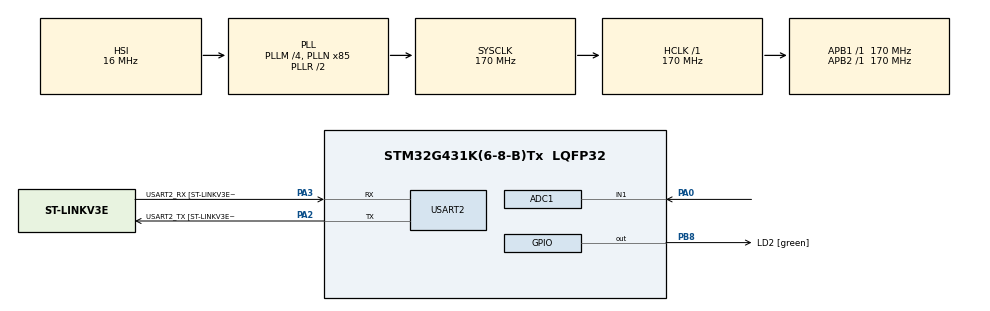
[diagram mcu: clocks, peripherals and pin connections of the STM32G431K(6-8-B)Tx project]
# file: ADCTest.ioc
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ADC1.Channel-0\#ChannelRegularConversion=ADC_CHANNEL_1
ADC1.NbrOfConversionFlag=1
ADC1.OffsetNumber-0\#ChannelRegularConversion=ADC_OFFSET_NONE
ADC1.Rank-0\#ChannelRegularConversion=1
ADC1.SamplingTime-0\#ChannelRegularConversion=ADC_SAMPLETIME_2CYCLES_5
ADC1.master=1
Mcu.Family=STM32G4
Mcu.Name=STM32G431K(6-8-B)Tx
Mcu.Package=LQFP32
NVIC.PriorityGroup=NVIC_PRIORITYGROUP_4
PA0.Mode=IN1-Single-Ended
PA0.Signal=ADC1_IN1
PA13.GPIO_Label=T_SWDIO
PA13.Mode=Serial_Wire
PA13.Signal=SYS_JTMS-SWDIO
PA14.GPIO_Label=T_SWCLK
PA14.Mode=Serial_Wire
PA14.Signal=SYS_JTCK-SWCLK
PA2.GPIO_Label=USART2_TX [ST-LINKV3E_VCP_RX]
PA2.Mode=Asynchronous
PA2.Signal=USART2_TX
PA3.GPIO_Label=USART2_RX [ST-LINKV3E_VCP_TX]
PA3.Mode=Asynchronous
PA3.Signal=USART2_RX
PB3.GPIO_Label=T_SWO
PB3.Signal=SYS_JTDO-SWO
PB8-BOOT0.GPIO_Label=LD2 [green]
PB8-BOOT0.Signal=GPIO_Output
ProjectManager.HeapSize=0x200
ProjectManager.StackSize=0x400
ProjectManager.TargetToolchain=STM32CubeIDE
RCC.ADC12Freq_Value=170000000
RCC.AHBFreq_Value=170000000
RCC.APB1Freq_Value=170000000
RCC.APB1TimFreq_Value=170000000
RCC.APB2Freq_Value=170000000
RCC.APB2TimFreq_Value=170000000
RCC.CortexFreq_Value=170000000
RCC.EXTERNAL_CLOCK_VALUE=12288000
RCC.HCLKFreq_Value=170000000
RCC.HSE_VALUE=8000000
RCC.HSI48_VALUE=48000000
RCC.HSI_VALUE=16000000
RCC.LSE_VALUE=32768
RCC.PLLM=RCC_PLLM_DIV4
RCC.PLLN=85
RCC.SYSCLKFreq_VALUE=170000000
RCC.SYSCLKSource=RCC_SYSCLKSOURCE_PLLCLK
RCC.USBFreq_Value=170000000
RCC.VCOOutputFreq_Value=340000000
USART2.VirtualMode-Asynchronous=VM_ASYNC
USART2.WordLength=WORDLENGTH_8B
board=NUCLEO-G431KB

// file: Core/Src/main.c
/* USER CODE BEGIN Header */
/**
  ******************************************************************************
  * @file           : main.c
  * @brief          : Main program body
  ******************************************************************************
  * @attention
  *
  * Copyright (c) 2022 STMicroelectronics.
  * All rights reserved.
  *
  * This software is licensed under terms that can be found in the LICENSE file
  * in the root directory of this software component.
  * If no LICENSE file comes with this software, it is provided AS-IS.
  *
  ******************************************************************************
  */
/* USER CODE END Header */
#include "main.h"

ADC_HandleTypeDef hadc1;

UART_HandleTypeDef huart2;

void SystemClock_Config(void);
static void MX_GPIO_Init(void);
static void MX_USART2_UART_Init(void);
static void MX_ADC1_Init(void);

int main(void)
{
  /* USER CODE BEGIN 1 */
	__IO uint32_t ad;
	//double v;
	uint8_t buff[10];
  /* USER CODE END 1 */

  /* MCU Configuration--------------------------------------------------------*/

  /* Reset of all peripherals, Initializes the Flash interface and the Systick. */
  HAL_Init();

  /* Configure the system clock */
  SystemClock_Config();

  /* Initialize all configured peripherals */
  MX_GPIO_Init();
  MX_USART2_UART_Init();
  MX_ADC1_Init();

  /* Infinite loop */
  /* USER CODE BEGIN WHILE */
  while (1)
  {
	  HAL_ADC_Start(&hadc1);
	 if (HAL_ADC_PollForConversion(&hadc1, 1000) == HAL_OK){
		 ad = HAL_ADC_GetValue(&hadc1);
		 //v = 3.3 * ad / 4095
	 }
	 HAL_ADC_Stop(&hadc1);

	 snprintf(buff, sizeof(buff), "%d", ad);
	 	  HAL_UART_Transmit(&huart2, buff, sizeof(buff), 100);
	 	  HAL_Delay(100);
    /* USER CODE END WHILE */

  }
}

void SystemClock_Config(void)
{
  RCC_OscInitTypeDef RCC_OscInitStruct = {0};
  RCC_ClkInitTypeDef RCC_ClkInitStruct = {0};

  /** Configure the main internal regulator output voltage
  */
  HAL_PWREx_ControlVoltageScaling(PWR_REGULATOR_VOLTAGE_SCALE1_BOOST);

  /** Initializes the RCC Oscillators according to the specified parameters
  * in the RCC_OscInitTypeDef structure.
  */
  RCC_OscInitStruct.OscillatorType = RCC_OSCILLATORTYPE_HSI;
  RCC_OscInitStruct.HSIState = RCC_HSI_ON;
  RCC_OscInitStruct.HSICalibrationValue = RCC_HSICALIBRATION_DEFAULT;
  RCC_OscInitStruct.PLL.PLLState = RCC_PLL_ON;
  RCC_OscInitStruct.PLL.PLLSource = RCC_PLLSOURCE_HSI;
  RCC_OscInitStruct.PLL.PLLM = RCC_PLLM_DIV4;
  RCC_OscInitStruct.PLL.PLLN = 85;
  RCC_OscInitStruct.PLL.PLLP = RCC_PLLP_DIV2;
  RCC_OscInitStruct.PLL.PLLQ = RCC_PLLQ_DIV2;
  RCC_OscInitStruct.PLL.PLLR = RCC_PLLR_DIV2;
  if (HAL_RCC_OscConfig(&RCC_OscInitStruct) != HAL_OK)
  {
    Error_Handler();
  }

  /** Initializes the CPU, AHB and APB buses clocks
  */
  RCC_ClkInitStruct.ClockType = RCC_CLOCKTYPE_HCLK|RCC_CLOCKTYPE_SYSCLK
                              |RCC_CLOCKTYPE_PCLK1|RCC_CLOCKTYPE_PCLK2;
  RCC_ClkInitStruct.SYSCLKSource = RCC_SYSCLKSOURCE_PLLCLK;
  RCC_ClkInitStruct.AHBCLKDivider = RCC_SYSCLK_DIV1;
  RCC_ClkInitStruct.APB1CLKDivider = RCC_HCLK_DIV1;
  RCC_ClkInitStruct.APB2CLKDivider = RCC_HCLK_DIV1;

  if (HAL_RCC_ClockConfig(&RCC_ClkInitStruct, FLASH_LATENCY_4) != HAL_OK)
  {
    Error_Handler();
  }
}

static void MX_ADC1_Init(void)
{

  ADC_MultiModeTypeDef multimode = {0};
  ADC_ChannelConfTypeDef sConfig = {0};

  /** Common config
  */
  hadc1.Instance = ADC1;
  hadc1.Init.ClockPrescaler = ADC_CLOCK_SYNC_PCLK_DIV4;
  hadc1.Init.Resolution = ADC_RESOLUTION_12B;
  hadc1.Init.DataAlign = ADC_DATAALIGN_RIGHT;
  hadc1.Init.GainCompensation = 0;
  hadc1.Init.ScanConvMode = ADC_SCAN_DISABLE;
  hadc1.Init.EOCSelection = ADC_EOC_SINGLE_CONV;
  hadc1.Init.LowPowerAutoWait = DISABLE;
  hadc1.Init.ContinuousConvMode = DISABLE;
  hadc1.Init.NbrOfConversion = 1;
  hadc1.Init.DiscontinuousConvMode = DISABLE;
  hadc1.Init.ExternalTrigConv = ADC_SOFTWARE_START;
  hadc1.Init.ExternalTrigConvEdge = ADC_EXTERNALTRIGCONVEDGE_NONE;
  hadc1.Init.DMAContinuousRequests = DISABLE;
  hadc1.Init.Overrun = ADC_OVR_DATA_PRESERVED;
  hadc1.Init.OversamplingMode = DISABLE;
  if (HAL_ADC_Init(&hadc1) != HAL_OK)
  {
    Error_Handler();
  }

  /** Configure the ADC multi-mode
  */
  multimode.Mode = ADC_MODE_INDEPENDENT;
  if (HAL_ADCEx_MultiModeConfigChannel(&hadc1, &multimode) != HAL_OK)
  {
    Error_Handler();
  }

  /** Configure Regular Channel
  */
  sConfig.Channel = ADC_CHANNEL_1;
  sConfig.Rank = ADC_REGULAR_RANK_1;
  sConfig.SamplingTime = ADC_SAMPLETIME_2CYCLES_5;
  sConfig.SingleDiff = ADC_SINGLE_ENDED;
  sConfig.OffsetNumber = ADC_OFFSET_NONE;
  sConfig.Offset = 0;
  if (HAL_ADC_ConfigChannel(&hadc1, &sConfig) != HAL_OK)
  {
    Error_Handler();
  }

}

static void MX_USART2_UART_Init(void)
{

  huart2.Instance = USART2;
  huart2.Init.BaudRate = 115200;
  huart2.Init.WordLength = UART_WORDLENGTH_8B;
  huart2.Init.StopBits = UART_STOPBITS_1;
  huart2.Init.Parity = UART_PARITY_NONE;
  huart2.Init.Mode = UART_MODE_TX_RX;
  huart2.Init.HwFlowCtl = UART_HWCONTROL_NONE;
  huart2.Init.OverSampling = UART_OVERSAMPLING_16;
  huart2.Init.OneBitSampling = UART_ONE_BIT_SAMPLE_DISABLE;
  huart2.Init.ClockPrescaler = UART_PRESCALER_DIV1;
  huart2.AdvancedInit.AdvFeatureInit = UART_ADVFEATURE_NO_INIT;
  if (HAL_UART_Init(&huart2) != HAL_OK)
  {
    Error_Handler();
  }
  if (HAL_UARTEx_SetTxFifoThreshold(&huart2, UART_TXFIFO_THRESHOLD_1_8) != HAL_OK)
  {
    Error_Handler();
  }
  if (HAL_UARTEx_SetRxFifoThreshold(&huart2, UART_RXFIFO_THRESHOLD_1_8) != HAL_OK)
  {
    Error_Handler();
  }
  if (HAL_UARTEx_DisableFifoMode(&huart2) != HAL_OK)
  {
    Error_Handler();
  }

}

static void MX_GPIO_Init(void)
{
  GPIO_InitTypeDef GPIO_InitStruct = {0};

  /* GPIO Ports Clock Enable */
  __HAL_RCC_GPIOA_CLK_ENABLE();
  __HAL_RCC_GPIOB_CLK_ENABLE();

  /*Configure GPIO pin Output Level */
  HAL_GPIO_WritePin(LD2_GPIO_Port, LD2_Pin, GPIO_PIN_RESET);

  /*Configure GPIO pin : LD2_Pin */
  GPIO_InitStruct.Pin = LD2_Pin;
  GPIO_InitStruct.Mode = GPIO_MODE_OUTPUT_PP;
  GPIO_InitStruct.Pull = GPIO_NOPULL;
  GPIO_InitStruct.Speed = GPIO_SPEED_FREQ_LOW;
  HAL_GPIO_Init(LD2_GPIO_Port, &GPIO_InitStruct);

}

void Error_Handler(void)
{
  __disable_irq();
  while (1)
  {
  }
}
